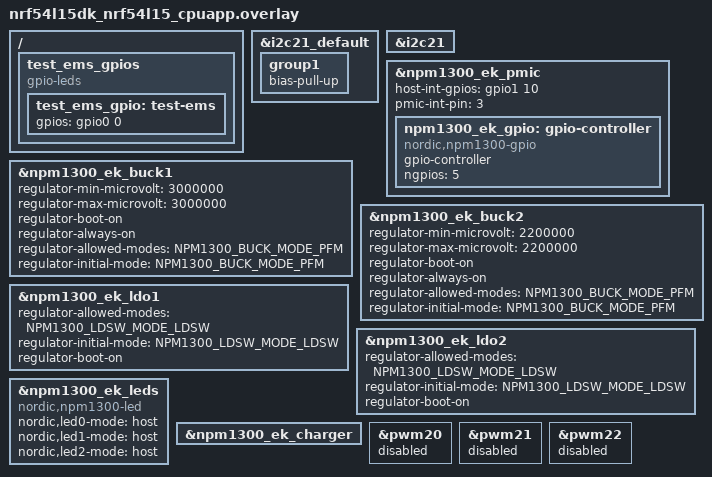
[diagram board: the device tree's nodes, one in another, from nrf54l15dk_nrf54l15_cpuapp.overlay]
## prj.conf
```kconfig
# Copyright (c) 2023 Nordic Semiconductor ASA
# SPDX-License-Identifier: LicenseRef-Nordic-5-Clause

CONFIG_SHELL=y
CONFIG_LOG=y
CONFIG_LOG_CMDS=y
CONFIG_GPIO=y
CONFIG_LED=y
CONFIG_REGULATOR=y
CONFIG_SENSOR=y
CONFIG_I2C_SHELL=y
CONFIG_NRF_FUEL_GAUGE=y
CONFIG_NRF_FUEL_GAUGE_VARIANT_SECONDARY_CELL=y
CONFIG_REQUIRES_FLOAT_PRINTF=y
CONFIG_MAIN_STACK_SIZE=1536

# Route console/printk/log/shell over SEGGER RTT instead of UART
CONFIG_SERIAL=n
CONFIG_UART_CONSOLE=n
CONFIG_USE_SEGGER_RTT=y
CONFIG_RTT_CONSOLE=y
CONFIG_CONSOLE=y
CONFIG_SHELL_BACKEND_SERIAL=n
CONFIG_SHELL_BACKEND_RTT=y
CONFIG_LOG_BACKEND_UART=n
CONFIG_LOG_BACKEND_RTT=y
CONFIG_LOG_BACKEND_RTT_BUFFER=1
CONFIG_SEGGER_RTT_BUFFER_SIZE_UP=4096
CONFIG_SEGGER_RTT_MAX_NUM_UP_BUFFERS=3

# EMS stimulation engine — nrfx-native PWM20/21/22 + GRTC syscounter
# (CONFIG_PWM stays unset: the engine drives nrfx directly)
CONFIG_NRFX_PWM20=y
CONFIG_NRFX_PWM21=y
CONFIG_NRFX_PWM22=y
CONFIG_NRFX_GRTC=y
CONFIG_NRF_GRTC_START_SYSCOUNTER=y

# to use internal 32 kHz crystal
CONFIG_CLOCK_CONTROL_NRF_K32SRC_RC=y
CONFIG_CLOCK_CONTROL_NRF_K32SRC_500PPM=y
CONFIG_CLOCK_CONTROL_NRF_K32SRC_RC_CALIBRATION=y
CONFIG_CLOCK_CONTROL_NRF_CALIBRATION_LF_ALWAYS_ON=y
```

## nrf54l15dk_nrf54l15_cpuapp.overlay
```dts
/*
 * Copyright (c) 2024 Nordic Semiconductor ASA
 *
 * SPDX-License-Identifier: LicenseRef-Nordic-5-Clause
 */

/* Original I2C configuration */
&i2c21_default {
    group1 {
        bias-pull-up;
    };
};

&i2c21 {
    status = "okay";
};

/* PMIC interrupt configuration */
&npm1300_ek_pmic {
    host-int-gpios = <&gpio1 10 0>;
    pmic-int-pin = <3>;

    /* Add GPIO controller node */
    npm1300_ek_gpio: gpio-controller {
        compatible = "nordic,npm1300-gpio";
        gpio-controller;
        #gpio-cells = <2>;
        ngpios = <5>;
        status = "okay";
    };
};

&npm1300_ek_buck1 {
	/* Set to your required rail; example: 1.8 V */
	regulator-min-microvolt = <3000000>;
	regulator-max-microvolt = <3000000>;

	/* Make sure it’s on at boot (and kept on) */
	regulator-boot-on;
	regulator-always-on;
	/* Enable forced PWM mode */
	regulator-allowed-modes = <NPM1300_BUCK_MODE_PFM>;
	regulator-initial-mode = <NPM1300_BUCK_MODE_PFM>;
	status = "okay";
};

&npm1300_ek_buck2 {
	/* Set to your required rail; example: 3.3 V */
	regulator-min-microvolt = <2200000>;
	regulator-max-microvolt = <2200000>;

	/* Make sure it's on at boot (and kept on) */
	regulator-boot-on;
	regulator-always-on;
	/* Enable forced PWM mode */
	regulator-allowed-modes = <NPM1300_BUCK_MODE_PFM>;
	regulator-initial-mode = <NPM1300_BUCK_MODE_PFM>;
	status = "okay";
};

/* Configure LDO1 in Load Switch mode */
&npm1300_ek_ldo1 {
	regulator-allowed-modes = <NPM1300_LDSW_MODE_LDSW>;
	regulator-initial-mode = <NPM1300_LDSW_MODE_LDSW>;
	regulator-boot-on;
	status = "okay";
};

/* Configure LDO2 as a regulated 3.3 V rail.
 * Output = 3.3 V when enabled, 0 V when disabled.
 * Control at runtime with regulator_enable() / regulator_disable().
 */
&npm1300_ek_ldo2 {
	regulator-allowed-modes = <NPM1300_LDSW_MODE_LDSW>;
	regulator-initial-mode = <NPM1300_LDSW_MODE_LDSW>;
	regulator-boot-on;
	status = "okay";
};

/* LED configuration - for RGB test */
&npm1300_ek_leds {
    compatible = "nordic,npm1300-led";
    nordic,led0-mode = "host";  /* Red LED - controlled by host */
    nordic,led1-mode = "host";  /* Green LED - controlled by host */
    nordic,led2-mode = "host";  /* Blue LED - controlled by host */
    status = "okay";
};

/* Charger configuration - for fuel gauge */
&npm1300_ek_charger {
    status = "okay";
};

/* ─── EMS stimulation engine ─── */

/* nrfx owns PWM20/21/22 directly (EasyDMA) — disable the Zephyr PWM driver
 * nodes so they don't claim the peripherals/pins. */
&pwm20 { status = "disabled"; };
&pwm21 { status = "disabled"; };
&pwm22 { status = "disabled"; };

/* EMS inductor-discharge safety GPIO — P0.0 (driven directly via nrf_gpio). */
/ {
    test_ems_gpios {
        compatible = "gpio-leds";
        test_ems_gpio: test-ems {
            gpios = <&gpio0 0 GPIO_ACTIVE_HIGH>;
        };
    };
};
```

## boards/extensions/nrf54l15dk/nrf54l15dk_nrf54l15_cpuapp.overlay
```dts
/*
 * Copyright (c) 2024 Nordic Semiconductor ASA
 *
 * SPDX-License-Identifier: LicenseRef-Nordic-5-Clause
 */

&pinctrl {
	i2c21_default: i2c21_default {
		group1 {
			psels = <NRF_PSEL(TWIM_SDA, 1, 12)>,
				<NRF_PSEL(TWIM_SCL, 1, 9)>;
		};
	};

	i2c21_sleep: i2c21_sleep {
		group1 {
			psels = <NRF_PSEL(TWIM_SDA, 1, 12)>,
				<NRF_PSEL(TWIM_SCL, 1, 9)>;
			low-power-enable;
		};
	};
};

/* Define arduino_i2c here so it is available for the shield overlay */
arduino_i2c: &i2c21 {
	compatible = "nordic,nrf-twim";
	pinctrl-0 = <&i2c21_default>;
	pinctrl-1 = <&i2c21_sleep>;
	pinctrl-names = "default", "sleep";
};
```

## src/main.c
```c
/*
 * NPM1300 + EMS Stimulation — Dual-Thread Application
 * Target: nrf54l15dk_nrf54l15_cpuapp
 *
 * Two concurrent Zephyr threads:
 *   Thread 1 (led_gpio): blinks the nPM1300 RGB LEDs and toggles nPM1300
 *                        GPIO1/2/3 as a heartbeat. Talks to the PMIC over
 *                        I2C only. Does NOT toggle any power rail.
 *   Thread 2 (stim):     EMS stimulation session manager. The waveform itself
 *                        is generated by the engine's GRTC + PWM interrupts;
 *                        this thread just starts a session, waits for it to
 *                        self-complete, and (optionally) loops.
 *
 * Power rails are set up ONCE at boot and never toggled: LS1 (the EMS
 * high-voltage stim rail) is enabled and left on; LS2 / VOUT1 / bucks are
 * left at their overlay/boot defaults.
 *
 * To change stimulation behavior, edit the EMS_* / LED_* #define block below.
 */

#include <zephyr/kernel.h>
#include <zephyr/device.h>
#include <zephyr/drivers/gpio.h>
#include <zephyr/drivers/led.h>
#include <zephyr/drivers/mfd/npm1300.h>
#include <zephyr/drivers/regulator.h>
#include <zephyr/sys/printk.h>

#include "ems_hw/ems_engine.h"

/* ═══════════════════════════════════════════════════════════════════
 *  Tunables — edit this block to change behavior
 * ═══════════════════════════════════════════════════════════════════ */

/* ─── EMS stimulation parameters ─── */
#define EMS_MODE              EMS_MODE_RELAX  /* SLEEP / RELAX / BREATH / CUSTOM preset */
#define EMS_INTENSITY         40              /* 1..100 */
#define EMS_PULSE_WIDTH_PCT   90              /* 1..100 */
#define EMS_SESSION_SECONDS   1200            /* bounded run; engine self-stops. 0 = infinite */
#define EMS_CONTINUOUS        0               /* 0 = one session then idle, 1 = loop forever */
#define EMS_INTERSESSION_MS   2000            /* gap between sessions when EMS_CONTINUOUS=1 */
#define EMS_PROGRESS_LOG_S    10              /* print a "still running" line every N seconds */

/* HV stim rail — one-line retarget to LS2 (ldsw2) or a buck if the PCB feeds
 * the stim inductor differently. Enabled ONCE at boot and left on. */
#define EMS_STIM_RAIL  ldsw1

/* ─── LED / GPIO heartbeat ─── */
#define LED_BLINK_PERIOD_MS   2000            /* half-period: LEDs/GPIO toggle every 2 s */

/* ─── Thread configuration ─── */
#define LED_STACK_SIZE   1024
#define STIM_STACK_SIZE  1024
#define LED_PRIORITY     8                    /* lowest: non-critical heartbeat */
#define STIM_PRIORITY    7                    /* below ems_wq (6) so it never starves it */

/* ═══════════════════════════════════════════════════════════════════
 *  EMS engine work queue
 *
 *  ems_engine.c declares `extern struct k_work_q ems_wq;` and schedules its
 *  inductor-discharge work on it. In the full DUSQ firmware this queue is
 *  created by the system init layer; here we provide a minimal queue so the
 *  engine drops in unmodified. Priority 6 mirrors the DUSQ ems_wq.
 * ═══════════════════════════════════════════════════════════════════ */
#define EMS_WQ_STACK_SIZE 1024
#define EMS_WQ_PRIORITY   6
K_THREAD_STACK_DEFINE(ems_wq_stack, EMS_WQ_STACK_SIZE);
struct k_work_q ems_wq;

/* ═══════════════════════════════════════════════════════════════════
 *  Device handles
 * ═══════════════════════════════════════════════════════════════════ */
static const struct device *pmic     = DEVICE_DT_GET(DT_NODELABEL(npm1300_ek_pmic));
static const struct device *leds     = DEVICE_DT_GET(DT_NODELABEL(npm1300_ek_leds));
static const struct device *npm_gpio = DEVICE_DT_GET(DT_NODELABEL(npm1300_ek_gpio));
static const struct device *ldsw1    = DEVICE_DT_GET(DT_NODELABEL(npm1300_ek_ldo1));

/* ═══════════════════════════════════════════════════════════════════
 *  Thread storage
 * ═══════════════════════════════════════════════════════════════════ */
K_THREAD_STACK_DEFINE(led_stack, LED_STACK_SIZE);
K_THREAD_STACK_DEFINE(stim_stack, STIM_STACK_SIZE);
static struct k_thread led_tcb;
static struct k_thread stim_tcb;

/* ═══════════════════════════════════════════════════════════════════
 *  Thread 1 — LED + GPIO heartbeat (I2C only, no rail toggling)
 *
 *  Independent of the stim thread: toggles the nPM1300 RGB LEDs + GPIO1/2/3
 *  every LED_BLINK_PERIOD_MS. Devices are verified ready and GPIO1/2/3 are
 *  configured as outputs in main() before this thread is created, so the
 *  loop only does set/clear.
 * ═══════════════════════════════════════════════════════════════════ */
static void led_gpio_thread(void *a, void *b, void *c)
{
    ARG_UNUSED(a);
    ARG_UNUSED(b);
    ARG_UNUSED(c);

    printk("[led] heartbeat started (%d ms)\n", LED_BLINK_PERIOD_MS);

    /* One full on+off cycle = 2 * LED_BLINK_PERIOD_MS. Log roughly every
     * EMS_PROGRESS_LOG_S seconds so the RTT shows this thread running in
     * parallel with the stim thread. */
    const uint32_t blinks_per_log =
        (EMS_PROGRESS_LOG_S * 1000U) / (2U * LED_BLINK_PERIOD_MS);
    uint32_t cycles = 0;

    bool on = false;
    for (;;) {
        on = !on;

        if (on) {
            led_on(leds, 0U);  /* Red   */
            led_on(leds, 1U);  /* Green */
            led_on(leds, 2U);  /* Blue  */
            gpio_pin_set(npm_gpio, 1, 1);
            gpio_pin_set(npm_gpio, 2, 1);
            gpio_pin_set(npm_gpio, 3, 1);
        } else {
            led_off(leds, 0U);
            led_off(leds, 1U);
            led_off(leds, 2U);
            gpio_pin_set(npm_gpio, 1, 0);
            gpio_pin_set(npm_gpio, 2, 0);
            gpio_pin_set(npm_gpio, 3, 0);

            /* Falling edge completes one full on+off cycle. */
            if (blinks_per_log && (++cycles % blinks_per_log == 0)) {
                printk("[led] heartbeat alive (%u cycles)\n", cycles);
            }
        }

        k_msleep(LED_BLINK_PERIOD_MS);
    }
}

/* ═══════════════════════════════════════════════════════════════════
 *  Thread 2 — EMS stimulation session manager
 *
 *  ems_init(), the one-time LS1 enable, and parameter setup are all done in
 *  main() before this thread is created. The engine generates the actual
 *  carrier/burst/rest waveform from GRTC + PWM ISRs; this thread only
 *  sequences sessions.
 *
 *  HV SAFETY: LS1 stays energized for the whole runtime, so we deliberately
 *  do NOT call ems_discharge_after_stop() here — driving the P0.0 inductor
 *  bleed against a live rail is the backfeed condition the engine warns
 *  against. ems_stop() alone returns the engine to a safe IDLE state (PWM
 *  released, P0.0 LOW). A true discharge only happens on reset/power-off.
 * ═══════════════════════════════════════════════════════════════════ */
static void stim_thread(void *a, void *b, void *c)
{
    ARG_UNUSED(a);
    ARG_UNUSED(b);
    ARG_UNUSED(c);

    do {
        int ret = ems_start();   /* acquires PWM20/21/22, dispatches ENABLE */
        if (ret < 0) {
            printk("[stim] ems_start failed (%d)\n", ret);
            break;
        }
        printk("[stim] session started (mode=%d, intensity=%d, %d s)\n",
               EMS_MODE, EMS_INTENSITY, EMS_SESSION_SECONDS);

        /* Engine self-stops at the session cycle limit; poll until IDLE.
         * Emit a periodic "still running" line so the run is visibly alive
         * (the engine itself can't safely printk from its GRTC ISR). */
        uint32_t elapsed_ms = 0;
        while (ems_get_state() != EMS_STATE_IDLE) {
            k_msleep(200);
            elapsed_ms += 200;
            if (elapsed_ms % (EMS_PROGRESS_LOG_S * 1000U) == 0) {
                printk("[stim] running... state=%d, elapsed=%u s\n",
                       (int)ems_get_state(), elapsed_ms / 1000U);
            }
        }

        ems_stop();              /* idempotent; releases PWM, drives P0.0 LOW */
        printk("[stim] session complete\n");

        if (EMS_CONTINUOUS) {
            k_msleep(EMS_INTERSESSION_MS);
        }
    } while (EMS_CONTINUOUS);

    /* One-shot path: idle forever (LED thread keeps blinking). */
    for (;;) {
        k_msleep(60000);
    }
}

/* ═══════════════════════════════════════════════════════════════════
 *  main — init, then launch the two worker threads
 * ═══════════════════════════════════════════════════════════════════ */
int main(void)
{
    int ret;

    printk("\n========================================\n");
    printk("  NPM1300 + EMS Dual-Thread Application\n");
    printk("  Version: 2.0\n");
    printk("========================================\n\n");

    /* 1) Start the EMS engine work queue BEFORE ems_init() — the engine
     *    schedules its boot-grace discharge work on this queue. */
    k_work_queue_init(&ems_wq);
    k_work_queue_start(&ems_wq, ems_wq_stack,
                       K_THREAD_STACK_SIZEOF(ems_wq_stack),
                       EMS_WQ_PRIORITY, NULL);

    /* 2) Device readiness — ALL checks are NON-FATAL.
     *
     *    The EMS engine generates its waveform from the nRF54L15's own PWM +
     *    GRTC peripherals and does NOT depend on the nPM1300. So a missing or
     *    undetected PMIC must NOT stop stimulation — only the LED/GPIO
     *    heartbeat (I2C) and the HV stim rail (LS1) depend on the PMIC. We
     *    record what's available and degrade gracefully. */
    bool pmic_ok = device_is_ready(pmic);
    bool leds_ok = device_is_ready(leds);
    bool gpio_ok = device_is_ready(npm_gpio);
    bool rail_ok = device_is_ready(EMS_STIM_RAIL);

    printk("Devices — PMIC:%s  LEDs:%s  GPIO:%s  LS1:%s\n",
           pmic_ok ? "ok" : "MISSING", leds_ok ? "ok" : "MISSING",
           gpio_ok ? "ok" : "MISSING", rail_ok ? "ok" : "MISSING");

    /* 3) Initialize the EMS engine (GRTC channels, P0.0 discharge pin,
     *    60 s boot-grace discharge hold). This is the ONLY hard requirement
     *    for stimulation — it is independent of the PMIC. */
    ret = ems_init();
    if (ret < 0) {
        printk("✗ ems_init failed (%d) — no stimulation possible. Halting.\n", ret);
        return 0;
    }

    /* 4) Bring up the HV stim rail if LS1 is present. If not, the engine
     *    STILL drives PWM on P1.13/P1.11/P1.07 — you can scope the signals,
     *    there's just no high voltage behind them. One-time enable; never
     *    toggled again. */
    if (rail_ok) {
        ret = regulator_enable(EMS_STIM_RAIL);
        if (ret < 0) {
            printk("⚠ LS1 enable failed (%d) — running stim WITHOUT HV rail\n", ret);
        } else {
            printk("✓ EMS stim rail (LS1) enabled (stays on)\n");
        }
    } else {
        printk("⚠ LS1 unavailable — stim PWM still generated, but NO high voltage\n");
    }

    /* 5) Apply EMS parameters ONCE. Order matters: mode first (loads the
     *    timing preset), then intensity/pulse-width, then session duration
     *    LAST — ems_set_session_duration() derives the cycle limit from the
     *    mode's stim+rest timing, which must already be populated. */
    ems_set_mode(EMS_MODE);
    ems_set_intensity(EMS_INTENSITY);
    ems_set_pulse_width(EMS_PULSE_WIDTH_PCT);
    ems_set_session_duration(EMS_SESSION_SECONDS);

    /* 6) Launch the stim thread — ALWAYS. It needs neither the PMIC nor the
     *    rail to generate the PWM waveform. */
    k_thread_create(&stim_tcb, stim_stack, K_THREAD_STACK_SIZEOF(stim_stack),
                    stim_thread, NULL, NULL, NULL,
                    STIM_PRIORITY, 0, K_NO_WAIT);
    k_thread_name_set(&stim_tcb, "stim");
    printk("✓ stim thread launched (prio %d)\n", STIM_PRIORITY);

    /* 7) Launch the LED/GPIO heartbeat thread ONLY if the PMIC stack is up
     *    (it drives the nPM1300 LEDs/GPIOs over I2C). Configure GPIO1/2/3 as
     *    outputs first so the thread only has to set/clear them. */
    if (pmic_ok && leds_ok && gpio_ok) {
        ret = gpio_pin_configure(npm_gpio, 1, GPIO_OUTPUT_INACTIVE);
        ret |= gpio_pin_configure(npm_gpio, 2, GPIO_OUTPUT_INACTIVE);
        ret |= gpio_pin_configure(npm_gpio, 3, GPIO_OUTPUT_INACTIVE);
        if (ret < 0) {
            printk("⚠ GPIO1/2/3 configure returned %d (heartbeat may be partial)\n", ret);
        }
        k_thread_create(&led_tcb, led_stack, K_THREAD_STACK_SIZEOF(led_stack),
                        led_gpio_thread, NULL, NULL, NULL,
                        LED_PRIORITY, 0, K_NO_WAIT);
        k_thread_name_set(&led_tcb, "led_gpio");
        printk("✓ led_gpio thread launched (prio %d)\n", LED_PRIORITY);
    } else {
        printk("⚠ PMIC stack not ready — LED/GPIO heartbeat DISABLED (stim still runs)\n");
    }

    return 0;
}
```

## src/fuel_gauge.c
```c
/*
 * Copyright (c) 2023 Nordic Semiconductor ASA
 * SPDX-License-Identifier: LicenseRef-Nordic-5-Clause
 */

#include <stdlib.h>

#include <zephyr/kernel.h>
#include <zephyr/device.h>
#include <zephyr/drivers/sensor.h>
#include <zephyr/drivers/sensor/npm1300_charger.h>
#include <zephyr/sys/printk.h>
#include <zephyr/sys/util.h>

#include <nrf_fuel_gauge.h>

/* nPM1300 CHARGER.BCHGCHARGESTATUS register bitmasks */
#define NPM1300_CHG_STATUS_COMPLETE_MASK BIT(1)
#define NPM1300_CHG_STATUS_TRICKLE_MASK	 BIT(2)
#define NPM1300_CHG_STATUS_CC_MASK	 BIT(3)
#define NPM1300_CHG_STATUS_CV_MASK	 BIT(4)

static int64_t ref_time;

static const struct battery_model battery_model = {
#include "battery_model.inc"
};

static int read_sensors(const struct device *charger, float *voltage, float *current, float *temp,
			int32_t *chg_status)
{
	struct sensor_value value;
	int ret;

	ret = sensor_sample_fetch(charger);
	if (ret < 0) {
		return ret;
	}

	sensor_channel_get(charger, SENSOR_CHAN_GAUGE_VOLTAGE, &value);
	*voltage = (float)value.val1 + ((float)value.val2 / 1000000);

	sensor_channel_get(charger, SENSOR_CHAN_GAUGE_TEMP, &value);
	*temp = (float)value.val1 + ((float)value.val2 / 1000000);

	sensor_channel_get(charger, SENSOR_CHAN_GAUGE_AVG_CURRENT, &value);
	*current = (float)value.val1 + ((float)value.val2 / 1000000);

	sensor_channel_get(charger, SENSOR_CHAN_NPM1300_CHARGER_STATUS, &value);
	*chg_status = value.val1;

	return 0;
}

static int charge_status_inform(int32_t chg_status)
{
	union nrf_fuel_gauge_ext_state_info_data state_info;

	if (chg_status & NPM1300_CHG_STATUS_COMPLETE_MASK) {
		printk("Charge complete\n");
		state_info.charge_state = NRF_FUEL_GAUGE_CHARGE_STATE_COMPLETE;
	} else if (chg_status & NPM1300_CHG_STATUS_TRICKLE_MASK) {
		printk("Trickle charging\n");
		state_info.charge_state = NRF_FUEL_GAUGE_CHARGE_STATE_TRICKLE;
	} else if (chg_status & NPM1300_CHG_STATUS_CC_MASK) {
		printk("Constant current charging\n");
		state_info.charge_state = NRF_FUEL_GAUGE_CHARGE_STATE_CC;
	} else if (chg_status & NPM1300_CHG_STATUS_CV_MASK) {
		printk("Constant voltage charging\n");
		state_info.charge_state = NRF_FUEL_GAUGE_CHARGE_STATE_CV;
	} else {
		printk("Charger idle\n");
		state_info.charge_state = NRF_FUEL_GAUGE_CHARGE_STATE_IDLE;
	}

	return nrf_fuel_gauge_ext_state_update(NRF_FUEL_GAUGE_EXT_STATE_INFO_CHARGE_STATE_CHANGE,
					       &state_info);
}

int fuel_gauge_init(const struct device *charger)
{
	struct sensor_value value;
	struct nrf_fuel_gauge_init_parameters parameters = {
		.model = &battery_model,
		.opt_params = NULL,
		.state = NULL,
	};
	float max_charge_current;
	float term_charge_current;
	int32_t chg_status;
	int ret;

	printk("nRF Fuel Gauge version: %s\n", nrf_fuel_gauge_version);

	ret = read_sensors(charger, &parameters.v0, &parameters.i0, &parameters.t0, &chg_status);
	if (ret < 0) {
		return ret;
	}

	/* Store charge nominal and termination current, needed for ttf calculation */
	sensor_channel_get(charger, SENSOR_CHAN_GAUGE_DESIRED_CHARGING_CURRENT, &value);
	max_charge_current = (float)value.val1 + ((float)value.val2 / 1000000);
	term_charge_current = max_charge_current / 10.f;

	ret = nrf_fuel_gauge_init(&parameters, NULL);
	if (ret < 0) {
		printk("Error: Could not initialise fuel gauge\n");
		return ret;
	}

	ret = nrf_fuel_gauge_ext_state_update(NRF_FUEL_GAUGE_EXT_STATE_INFO_CHARGE_CURRENT_LIMIT,
					      &(union nrf_fuel_gauge_ext_state_info_data){
						      .charge_current_limit = max_charge_current});
	if (ret < 0) {
		printk("Error: Could not set fuel gauge state\n");
		return ret;
	}

	ret = nrf_fuel_gauge_ext_state_update(NRF_FUEL_GAUGE_EXT_STATE_INFO_TERM_CURRENT,
					      &(union nrf_fuel_gauge_ext_state_info_data){
						      .charge_term_current = term_charge_current});
	if (ret < 0) {
		printk("Error: Could not set fuel gauge state\n");
		return ret;
	}

	ret = charge_status_inform(chg_status);
	if (ret < 0) {
		printk("Error: Could not set fuel gauge state\n");
		return ret;
	}

	ref_time = k_uptime_get();

	return 0;
}

int fuel_gauge_update(const struct device *charger, bool vbus_connected)
{
	static int32_t chg_status_prev;

	float voltage;
	float current;
	float temp;
	float soc;
	float tte;
	float ttf;
	float delta;
	int32_t chg_status;
	int ret;

	ret = read_sensors(charger, &voltage, &current, &temp, &chg_status);
	if (ret < 0) {
		printk("Error: Could not read from charger device\n");
		return ret;
	}

	ret = nrf_fuel_gauge_ext_state_update(
		vbus_connected ? NRF_FUEL_GAUGE_EXT_STATE_INFO_VBUS_CONNECTED
			       : NRF_FUEL_GAUGE_EXT_STATE_INFO_VBUS_DISCONNECTED,
		NULL);
	if (ret < 0) {
		printk("Error: Could not inform of state\n");
		return ret;
	}

	if (chg_status != chg_status_prev) {
		chg_status_prev = chg_status;

		ret = charge_status_inform(chg_status);
		if (ret < 0) {
			printk("Error: Could not inform of charge status\n");
			return ret;
		}
	}

	delta = (float)k_uptime_delta(&ref_time) / 1000.f;

	soc = nrf_fuel_gauge_process(voltage, current, temp, delta, NULL);
	tte = nrf_fuel_gauge_tte_get();
	ttf = nrf_fuel_gauge_ttf_get();

	printk("V: %.3f, I: %.3f, T: %.2f, ", (double)voltage, ((double)current*1000), (double)temp);
	printk("SoC: %.2f, TTE: %.0f, TTF: %.0f\n", (double)soc, (double)tte, (double)ttf);

	return 0;
}
```
